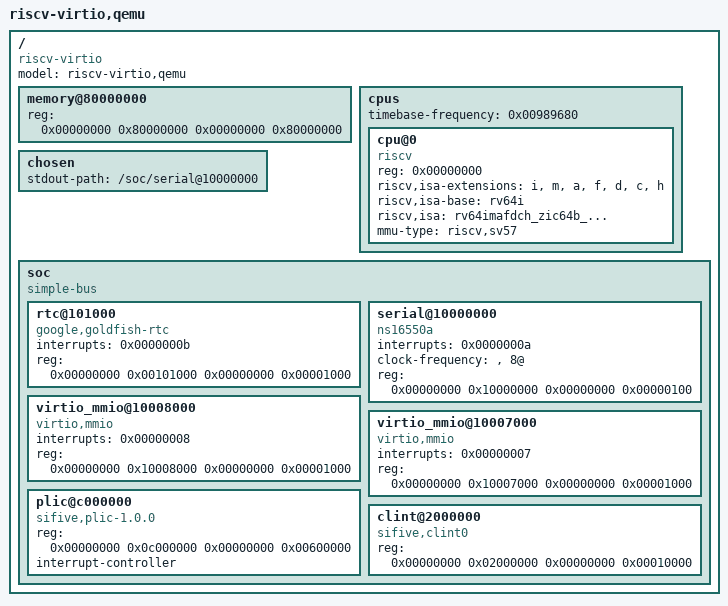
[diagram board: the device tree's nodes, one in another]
/ {
	compatible = "riscv-virtio";
	model = "riscv-virtio,qemu";
	memory@80000000 {
		device_type = "memory";
		reg = <0x00000000 0x80000000 0x00000000 0x80000000>;
	};
	cpus {
		timebase-frequency = <0x00989680>;
		cpu@0 {
			phandle = <0x00000001>;
			device_type = "cpu";
			reg = <0x00000000>;
			status = "okay";
			compatible = "riscv";
			riscv,isa-extensions = "i", "m", "a", "f", "d", "c", "h";
			riscv,isa-base = "rv64i";
			riscv,isa = "rv64imafdch_zic64b_...";
			mmu-type = "riscv,sv57";
		};
	};
	chosen {
		stdout-path = "/soc/serial@10000000";
	};
	soc {
		compatible = "simple-bus";
		ranges;
		rtc@101000 {
			interrupts = <0x0000000b>;
			reg = <0x00000000 0x00101000 0x00000000 0x00001000>;
			compatible = "google,goldfish-rtc";
		};
		serial@10000000 {
			interrupts = <0x0000000a>;
			clock-frequency = "", "8@";
			reg = <0x00000000 0x10000000 0x00000000 0x00000100>;
			compatible = "ns16550a";
		};
		virtio_mmio@10008000 {
			interrupts = <0x00000008>;
			reg = <0x00000000 0x10008000 0x00000000 0x00001000>;
			compatible = "virtio,mmio";
		};
		virtio_mmio@10007000 {
			interrupts = <0x00000007>;
			reg = <0x00000000 0x10007000 0x00000000 0x00001000>;
			compatible = "virtio,mmio";
		};
		plic@c000000 {
			reg = <0x00000000 0x0c000000 0x00000000 0x00600000>;
			interrupt-controller;
			compatible = "sifive,plic-1.0.0", "riscv,plic0";
		};
		clint@2000000 {
			reg = <0x00000000 0x02000000 0x00000000 0x00010000>;
			compatible = "sifive,clint0", "riscv,clint0";
		};
	};
};

